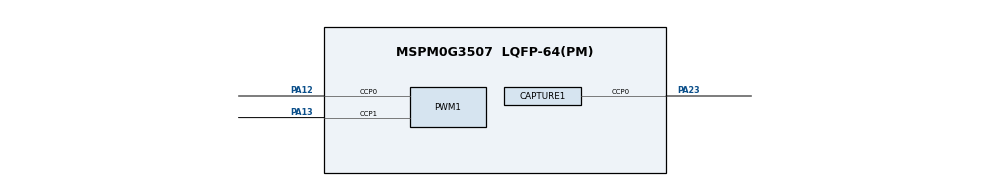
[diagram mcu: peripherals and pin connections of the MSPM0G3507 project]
/**
 * These arguments were used when this file was generated. They will be automatically applied on subsequent loads
 * via the GUI or CLI. Run CLI with '--help' for additional information on how to override these arguments.
 * @cliArgs --device "MSPM0G350X" --part "Default" --package "LQFP-64(PM)" --product "mspm0_sdk@2.10.00.04"
 * @v2CliArgs --device "MSPM0G3507" --package "LQFP-64(PM)" --product "mspm0_sdk@2.10.00.04"
 * @versions {"tool":"1.27.0+4565"}
 */

/**
 * Import the modules used in this configuration.
 */
const CAPTURE  = scripting.addModule("/ti/driverlib/CAPTURE", {}, false);
const CAPTURE1 = CAPTURE.addInstance();
const CAPTURE2 = CAPTURE.addInstance();
const GPIO     = scripting.addModule("/ti/driverlib/GPIO", {}, false);
const GPIO1    = GPIO.addInstance();
const GPIO2    = GPIO.addInstance();
const GPIO3    = GPIO.addInstance();
const GPIO4    = GPIO.addInstance();
const PWM      = scripting.addModule("/ti/driverlib/PWM", {}, false);
const PWM1     = PWM.addInstance();
const SYSCTL   = scripting.addModule("/ti/driverlib/SYSCTL");
const SYSTICK  = scripting.addModule("/ti/driverlib/SYSTICK");
const TIMER    = scripting.addModule("/ti/driverlib/TIMER", {}, false);
const TIMER1   = TIMER.addInstance();
const UART     = scripting.addModule("/ti/driverlib/UART", {}, false);
const UART1    = UART.addInstance();

/**
 * Write custom configuration values to the imported modules.
 */
const divider6       = system.clockTree["PLL_CLK2X_DIV"];
divider6.divideValue = 4;

const divider7       = system.clockTree["PLL_PDIV"];
divider7.divideValue = 2;

const divider9       = system.clockTree["UDIV"];
divider9.divideValue = 2;

const gate7  = system.clockTree["MFCLKGATE"];
gate7.enable = true;

const multiplier2         = system.clockTree["PLL_QDIV"];
multiplier2.multiplyValue = 10;

const mux8       = system.clockTree["HSCLKMUX"];
mux8.inputSelect = "HSCLKMUX_SYSPLL2X";

CAPTURE1.$name                              = "ENCODER1A";
CAPTURE1.interrupts                         = ["CC0_DN"];
CAPTURE1.timerClkDiv                        = 8;
CAPTURE1.timerPeriod                        = "1ms";
CAPTURE1.peripheral.ccp0Pin.$assign         = "PA23";
CAPTURE1.ccp0PinConfig.hideOutputInversion  = scripting.forceWrite(false);
CAPTURE1.ccp0PinConfig.onlyInternalResistor = scripting.forceWrite(false);
CAPTURE1.ccp0PinConfig.passedPeripheralType = scripting.forceWrite("Digital");
CAPTURE1.ccp0PinConfig.$name                = "ti_driverlib_gpio_GPIOPinGeneric2";

const Board = scripting.addModule("/ti/driverlib/Board", {}, false);

CAPTURE2.$name                              = "ENCODER2A";
CAPTURE2.timerClkDiv                        = 8;
CAPTURE2.timerPeriod                        = "1 ms";
CAPTURE2.interrupts                         = ["CC0_DN"];
CAPTURE2.ccp0PinConfig.hideOutputInversion  = scripting.forceWrite(false);
CAPTURE2.ccp0PinConfig.onlyInternalResistor = scripting.forceWrite(false);
CAPTURE2.ccp0PinConfig.passedPeripheralType = scripting.forceWrite("Digital");
CAPTURE2.ccp0PinConfig.$name                = "ti_driverlib_gpio_GPIOPinGeneric3";

GPIO1.$name                              = "GPIO_BEEP";
GPIO1.port                               = "PORTA";
GPIO1.associatedPins[0].$name            = "USER_BEEP";
GPIO1.associatedPins[0].assignedPin      = "27";
GPIO1.associatedPins[0].internalResistor = "PULL_DOWN";

GPIO2.$name                              = "GPIO_LEDS";
GPIO2.port                               = "PORTB";
GPIO2.associatedPins[0].$name            = "USER_LED_G";
GPIO2.associatedPins[0].assignedPin      = "27";
GPIO2.associatedPins[0].internalResistor = "PULL_DOWN";

GPIO3.$name                         = "GPIO_MOTOR_DIR";
GPIO3.port                          = "PORTA";
GPIO3.associatedPins.create(4);
GPIO3.associatedPins[0].$name       = "MOTOR_AIN1";
GPIO3.associatedPins[0].assignedPin = "0";
GPIO3.associatedPins[1].$name       = "MOTOR_AIN2";
GPIO3.associatedPins[1].assignedPin = "1";
GPIO3.associatedPins[2].$name       = "MOTOR_BIN1";
GPIO3.associatedPins[2].assignedPin = "2";
GPIO3.associatedPins[3].$name       = "MOTOR_BIN2";
GPIO3.associatedPins[3].assignedPin = "3";

GPIO4.$name                         = "GPIO_ENCODER";
GPIO4.port                          = "PORTA";
GPIO4.associatedPins.create(2);
GPIO4.associatedPins[0].$name       = "ENCODER1B";
GPIO4.associatedPins[0].direction   = "INPUT";
GPIO4.associatedPins[0].assignedPin = "24";
GPIO4.associatedPins[1].$name       = "ENCODER2B";
GPIO4.associatedPins[1].direction   = "INPUT";
GPIO4.associatedPins[1].assignedPin = "22";

PWM1.$name                              = "PWM_MOTOR";
PWM1.timerStartTimer                    = true;
PWM1.timerCount                         = 2000;
PWM1.peripheral.ccp0Pin.$assign         = "PA12";
PWM1.peripheral.ccp1Pin.$assign         = "PA13";
PWM1.PWM_CHANNEL_0.$name                = "ti_driverlib_pwm_PWMTimerCC0";
PWM1.PWM_CHANNEL_1.$name                = "ti_driverlib_pwm_PWMTimerCC1";
PWM1.ccp0PinConfig.direction            = scripting.forceWrite("OUTPUT");
PWM1.ccp0PinConfig.hideOutputInversion  = scripting.forceWrite(false);
PWM1.ccp0PinConfig.onlyInternalResistor = scripting.forceWrite(false);
PWM1.ccp0PinConfig.passedPeripheralType = scripting.forceWrite("Digital");
PWM1.ccp0PinConfig.$name                = "ti_driverlib_gpio_GPIOPinGeneric0";
PWM1.ccp1PinConfig.direction            = scripting.forceWrite("OUTPUT");
PWM1.ccp1PinConfig.hideOutputInversion  = scripting.forceWrite(false);
PWM1.ccp1PinConfig.onlyInternalResistor = scripting.forceWrite(false);
PWM1.ccp1PinConfig.passedPeripheralType = scripting.forceWrite("Digital");
PWM1.ccp1PinConfig.$name                = "ti_driverlib_gpio_GPIOPinGeneric1";

SYSCTL.forceDefaultClkConfig = true;
SYSCTL.clockTreeEn           = true;

SYSTICK.periodEnable      = true;
SYSTICK.period            = 80000;
SYSTICK.interruptEnable   = true;
SYSTICK.interruptPriority = "0";
SYSTICK.systickEnable     = true;

TIMER1.$name            = "CLOCK";
TIMER1.timerClkDiv      = 8;
TIMER1.timerClkPrescale = 100;
TIMER1.timerPeriod      = "10 ms";
TIMER1.interrupts       = ["ZERO"];
TIMER1.timerMode        = "PERIODIC";

UART1.$name                                = "UART_CAM";
UART1.uartClkSrc                           = "MFCLK";
UART1.enabledDMARXTriggers                 = "DL_UART_DMA_INTERRUPT_RX";
UART1.enabledInterrupts                    = ["DMA_DONE_RX"];
UART1.txPinConfig.$name                    = "ti_driverlib_gpio_GPIOPinGeneric4";
UART1.txPinConfig.direction                = scripting.forceWrite("OUTPUT");
UART1.txPinConfig.hideOutputInversion      = scripting.forceWrite(false);
UART1.txPinConfig.onlyInternalResistor     = scripting.forceWrite(false);
UART1.txPinConfig.passedPeripheralType     = scripting.forceWrite("Digital");
UART1.rxPinConfig.$name                    = "ti_driverlib_gpio_GPIOPinGeneric5";
UART1.rxPinConfig.hideOutputInversion      = scripting.forceWrite(false);
UART1.rxPinConfig.onlyInternalResistor     = scripting.forceWrite(false);
UART1.rxPinConfig.passedPeripheralType     = scripting.forceWrite("Digital");
UART1.DMA_CHANNEL_RX.configureTransferSize = true;
UART1.DMA_CHANNEL_RX.srcLength             = "BYTE";
UART1.DMA_CHANNEL_RX.dstLength             = "BYTE";
UART1.DMA_CHANNEL_RX.addressMode           = "f2b";
UART1.DMA_CHANNEL_RX.$name                 = "DMA_UART0_RX";
UART1.DMA_CHANNEL_RX.transferSize          = 8;

/**
 * Pinmux solution for unlocked pins/peripherals. This ensures that minor changes to the automatic solver in a future
 * version of the tool will not impact the pinmux you originally saw.  These lines can be completely deleted in order to
 * re-solve from scratch.
 */
CAPTURE1.peripheral.$suggestSolution             = "TIMG7";
Board.peripheral.$suggestSolution                = "DEBUGSS";
Board.peripheral.swclkPin.$suggestSolution       = "PA20";
Board.peripheral.swdioPin.$suggestSolution       = "PA19";
CAPTURE2.peripheral.$suggestSolution             = "TIMA1";
CAPTURE2.peripheral.ccp0Pin.$suggestSolution     = "PA15";
GPIO1.associatedPins[0].pin.$suggestSolution     = "PA27";
GPIO2.associatedPins[0].pin.$suggestSolution     = "PB27";
GPIO3.associatedPins[0].pin.$suggestSolution     = "PA0";
GPIO3.associatedPins[1].pin.$suggestSolution     = "PA1";
GPIO3.associatedPins[2].pin.$suggestSolution     = "PA2";
GPIO3.associatedPins[3].pin.$suggestSolution     = "PA3";
GPIO4.associatedPins[0].pin.$suggestSolution     = "PA24";
GPIO4.associatedPins[1].pin.$suggestSolution     = "PA22";
PWM1.peripheral.$suggestSolution                 = "TIMG0";
TIMER1.peripheral.$suggestSolution               = "TIMA0";
UART1.peripheral.$suggestSolution                = "UART0";
UART1.peripheral.rxPin.$suggestSolution          = "PA11";
UART1.peripheral.txPin.$suggestSolution          = "PA10";
UART1.DMA_CHANNEL_RX.peripheral.$suggestSolution = "DMA_CH0";
